# M470 register map
File version: 2.0.2.5
Registers are 32-bit, read-write, reset 0x0 unless marked. A register's access mark holds for its fields unless they carry their own. Offsets are from the block's base; [hi:lo] are bit positions; {n}, {i} and the like mark numbered series.

## PK — Port K
Base 0x400C0900
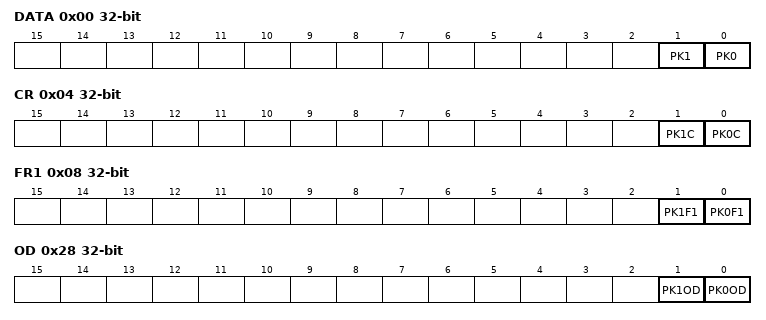
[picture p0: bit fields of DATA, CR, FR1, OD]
0x00 DATA — Port K Data Register
  [1] PK1, [0] PK0
0x04 CR — Port K Output Control Register
  [1] PK1C, [0] PK0C
0x08 FR1 — Port K Function Register 1
  [1] PK1F1, [0] PK0F1
0x28 OD — Port K Open Drain Control Register
  [1] PK1OD, [0] PK0OD
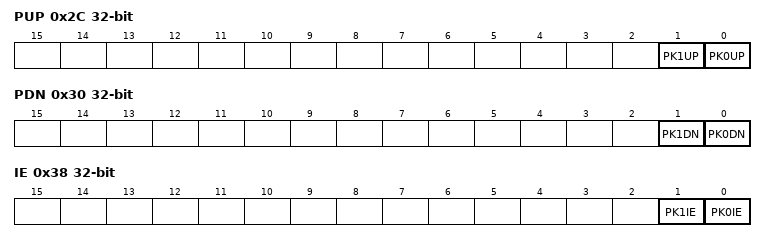
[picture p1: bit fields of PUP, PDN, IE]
0x2C PUP — Port K Pull-up Control Register
  [1] PK1UP, [0] PK0UP
0x30 PDN — Port K Pull-down Control Register
  [1] PK1DN, [0] PK0DN
0x38 IE — Port K Input Control Register
  [1] PK1IE, [0] PK0IE

## PL — Port L
Base 0x400C0A00
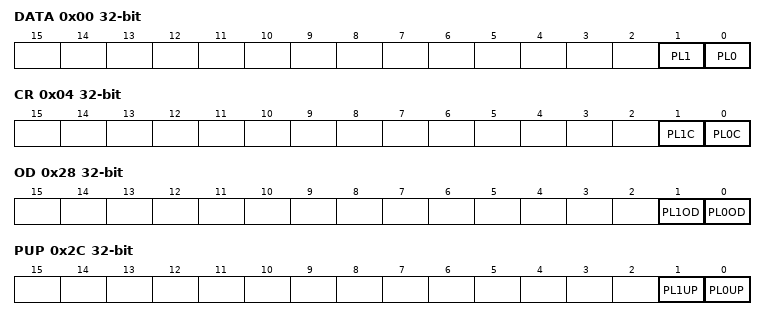
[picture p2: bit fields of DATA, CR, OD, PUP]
0x00 DATA — Port L Data Register
  [1] PL1, [0] PL0
0x04 CR — Port L Output Control Register
  [1] PL1C, [0] PL0C
0x28 OD — Port L Open Drain Control Register
  [1] PL1OD, [0] PL0OD
0x2C PUP — Port L Pull-up Control Register
  [1] PL1UP, [0] PL0UP
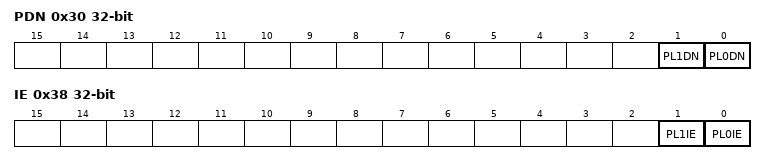
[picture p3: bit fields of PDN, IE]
0x30 PDN — Port L Pull-down Control Register
  [1] PL1DN, [0] PL0DN
0x38 IE — Port L Input Control Register
  [1] PL1IE, [0] PL0IE

## PN — Port N
Base 0x400C0C00
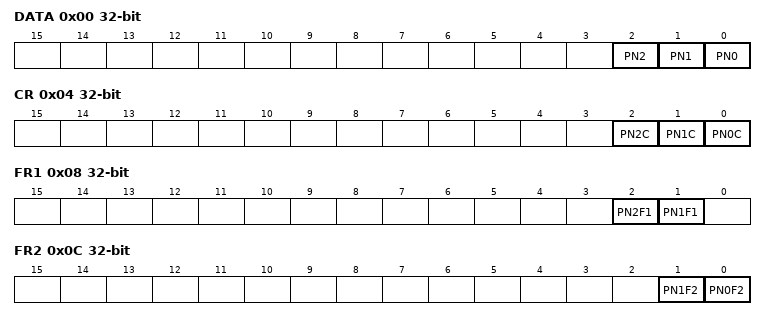
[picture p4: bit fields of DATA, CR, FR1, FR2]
0x00 DATA — Port N Data Register
  [2] PN2, [1] PN1, [0] PN0
0x04 CR — Port N Output Control Register
  [2] PN2C, [1] PN1C, [0] PN0C
0x08 FR1 — Port N Function Register 1
  [2] PN2F1, [1] PN1F1
0x0C FR2 — Port N Function Register 2
  [1] PN1F2, [0] PN0F2
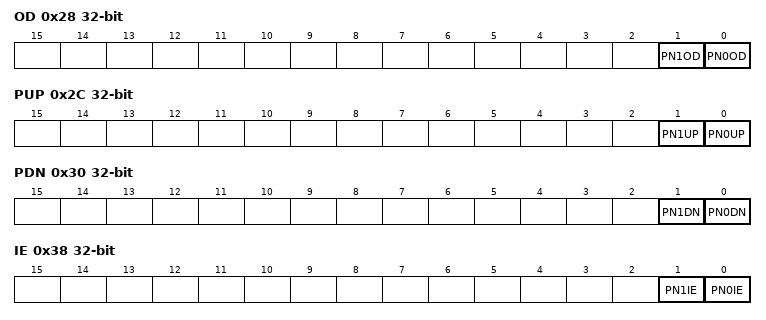
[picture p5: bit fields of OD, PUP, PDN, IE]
0x28 OD — Port N Open Drain Register
  [1] PN1OD, [0] PN0OD
0x2C PUP — Port N Pull-up Control Register
  [1] PN1UP, [0] PN0UP
0x30 PDN — Port N Pull-down Control Register
  [1] PN1DN, [0] PN0DN
0x38 IE — Port N Input Control Register
  [1] PN1IE, [0] PN0IE

## PP — Port P
Base 0x400C0D00
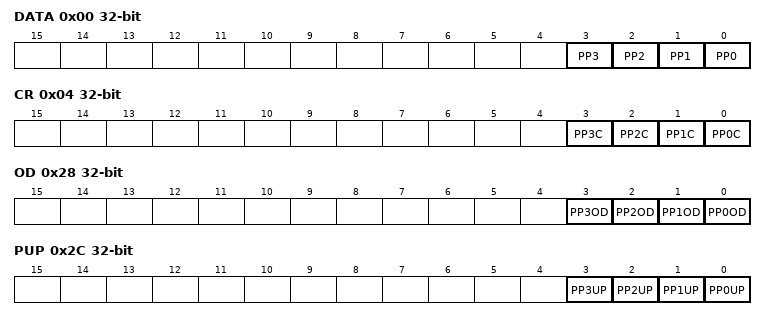
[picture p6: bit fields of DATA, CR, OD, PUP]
0x00 DATA — Port P Data Register
  [n] PP{n} (n=0..3)
0x04 CR — Port P Output Control Register
  [n] PP{n}C (n=0..3)
0x28 OD — Port P Open Drain Register
  [n] PP{n}OD (n=0..3)
0x2C PUP — Port P Pull-up Control Register
  [n] PP{n}UP (n=0..3)
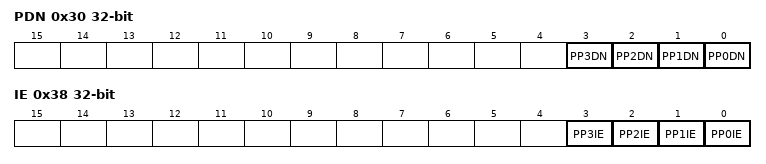
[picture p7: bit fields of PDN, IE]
0x30 PDN — Port P Pull-down Control Register
  [n] PP{n}DN (n=0..3)
0x38 IE — Port P Input Control Register
  [n] PP{n}IE (n=0..3)

## TB0 — 16-bit Timer _ Event Counters (TMRB)
Base 0x400C4000
Same registers: TB{n} {0x400C4000+0x100*n} (n=1..9)
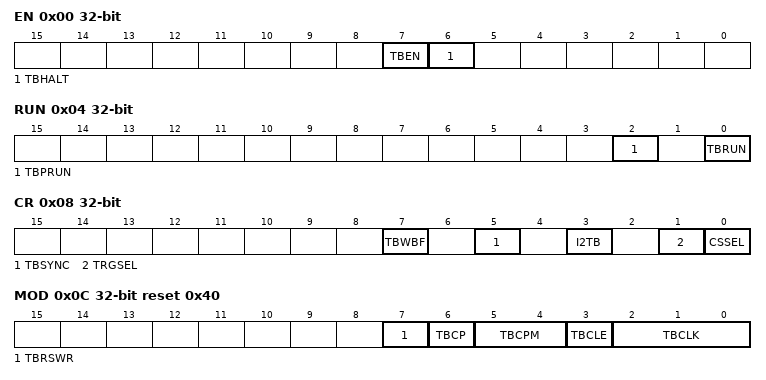
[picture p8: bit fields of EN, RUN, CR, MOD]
0x00 EN — TB Enable Register
  [7] TBEN, [6] TBHALT
0x04 RUN — TB RUN Register
  [2] TBPRUN, [0] TBRUN
0x08 CR — TB Control Register
  [7] TBWBF, [5] TBSYNC, [3] I2TB, [1] TRGSEL, [0] CSSEL
0x0C MOD reset 0x40 — TB Mode Register
  [7] TBRSWR, [6] TBCP wo, [5:4] TBCPM, [3] TBCLE, [2:0] TBCLK
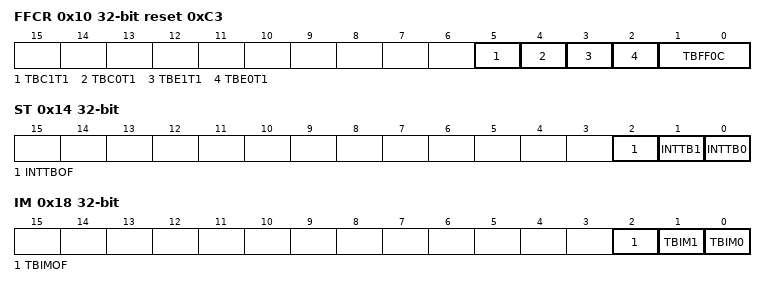
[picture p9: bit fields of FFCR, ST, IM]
0x10 FFCR reset 0xC3 — TB Flip-Flop Control Register
  [5] TBC1T1, [4] TBC0T1, [3] TBE1T1, [2] TBE0T1, [1:0] TBFF0C
0x14 ST ro — TB Status Register
  [2] INTTBOF, [1] INTTB1, [0] INTTB0
0x18 IM — TB Interrupt Mask Register
  [2] TBIMOF, [1] TBIM1, [0] TBIM0
0x1C UC ro — TB Up-counter Capture Register
  [15:0] UC
0x20 RG0 — TB RG0 Timer Register
  [15:0] TBRG0
0x24 RG1 — TB RG1 Timer Register
  [15:0] TBRG1
0x28 CP0 ro — TB CP0 Capture Register
  [15:0] TBCP0
0x2C CP1 ro — TB CP1 Capture Register
  [15:0] TBCP1

## SBI — Serial Bus Interface(SBI)
Base 0x400E0000
0x00 CR0 — SBI Control Register 0
  [7] SBIEN
0x04 CR1 reset 0x2 — SBI Control Register 1 (I2C Mode)
  [7:5] BC, [4] ACK, [0] SWRMON ro, [2:0] SCK wo
0x08 DBR — SBI Data Buffer Register
  [7:0] DB
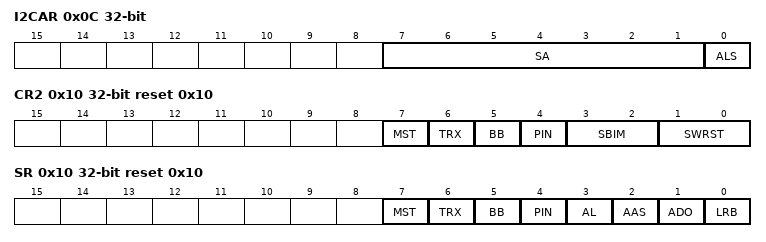
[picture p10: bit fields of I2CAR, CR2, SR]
0x0C I2CAR — SBI I2C Bus Address Register
  [7:1] SA, [0] ALS
0x10 CR2 wo reset 0x10 — SBI Control Register 2 (I2C Mode)
  [7] MST, [6] TRX, [5] BB, [4] PIN, [3:2] SBIM, [1:0] SWRST
0x10 SR ro reset 0x10 — SBI Status Register (I2C Mode)
  [7] MST, [6] TRX, [5] BB, [4] PIN, [3] AL, [2] AAS, [1] ADO, [0] LRB
0x14 BR0 reset 0xBE — SBI Baud Rate Register 0
  [6] I2SBI

## SC0 — Serial Channel (SC)
Base 0x400E1000
Same registers: SC1 0x400E1100, SC2 0x400E1200, SC3 0x400E1300
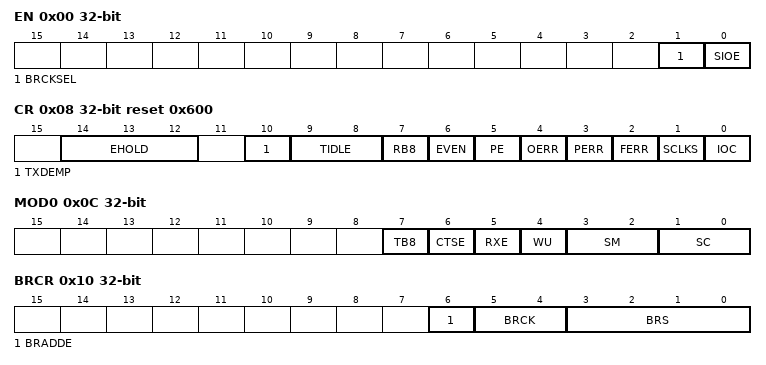
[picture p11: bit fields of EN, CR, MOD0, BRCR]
0x00 EN — SC Enable Register
  [1] BRCKSEL, [0] SIOE
0x04 BUF — SC Buffer Register
  [7:0] TR_RB
0x08 CR reset 0x600 — SC Control Register
  [14:12] EHOLD, [10] TXDEMP, [9:8] TIDLE, [7] RB8 ro, [6] EVEN, [5] PE, [4] OERR ro, [3] PERR ro, [2] FERR ro, [1] SCLKS, [0] IOC
0x0C MOD0 — SC Mode Control Register 0
  [7] TB8, [6] CTSE, [5] RXE, [4] WU, [3:2] SM, [1:0] SC
0x10 BRCR — SC Baud Rate Generator Control Register
  [6] BRADDE, [5:4] BRCK, [3:0] BRS
0x14 BRADD — SC Baud Rate Generator Control Register 2
  [3:0] BRK
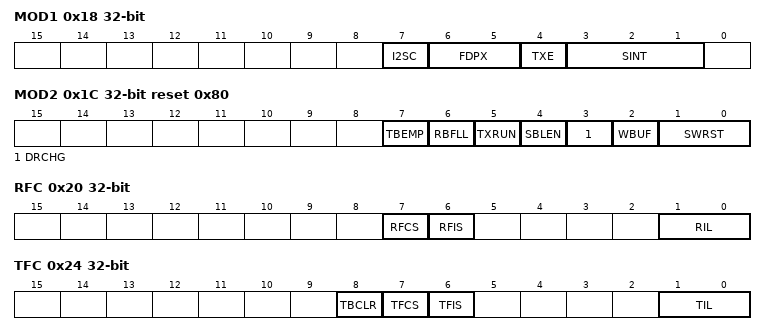
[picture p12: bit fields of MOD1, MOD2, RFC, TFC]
0x18 MOD1 — SC Mode Control Register 1
  [7] I2SC, [6:5] FDPX, [4] TXE, [3:1] SINT
0x1C MOD2 reset 0x80 — SC Mode Control Register 2
  [7] TBEMP ro, [6] RBFLL ro, [5] TXRUN ro, [4] SBLEN, [3] DRCHG, [2] WBUF, [1:0] SWRST
0x20 RFC — SC RX FIFO Configuration Register
  [7] RFCS wo, [6] RFIS, [1:0] RIL
0x24 TFC — SC TX FIFO Configuration Register
  [8] TBCLR wo, [7] TFCS wo, [6] TFIS, [1:0] TIL
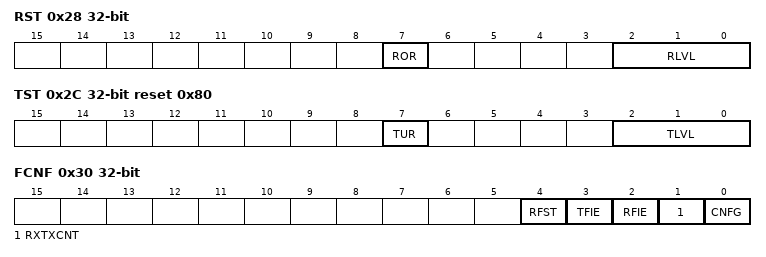
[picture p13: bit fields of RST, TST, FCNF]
0x28 RST ro — SC RX FIFO Status Register
  [7] ROR, [2:0] RLVL
0x2C TST ro reset 0x80 — SC TX FIFO Status Register
  [7] TUR, [2:0] TLVL
0x30 FCNF — SC FIFO Configuration Register
  [4] RFST, [3] TFIE, [2] RFIE, [1] RXTXCNT, [0] CNFG
